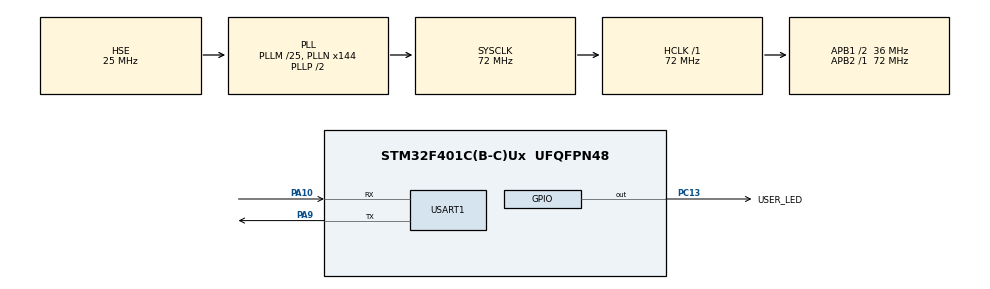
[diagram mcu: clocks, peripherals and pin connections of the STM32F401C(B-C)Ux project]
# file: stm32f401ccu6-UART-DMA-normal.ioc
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Dma.Request0=USART1_RX
Dma.USART1_RX.0.Direction=DMA_PERIPH_TO_MEMORY
Dma.USART1_RX.0.FIFOMode=DMA_FIFOMODE_DISABLE
Dma.USART1_RX.0.Instance=DMA2_Stream5
Dma.USART1_RX.0.MemDataAlignment=DMA_MDATAALIGN_BYTE
Dma.USART1_RX.0.MemInc=DMA_MINC_ENABLE
Dma.USART1_RX.0.Mode=DMA_NORMAL
Dma.USART1_RX.0.PeriphDataAlignment=DMA_PDATAALIGN_BYTE
Dma.USART1_RX.0.PeriphInc=DMA_PINC_DISABLE
Dma.USART1_RX.0.Priority=DMA_PRIORITY_LOW
Mcu.Family=STM32F4
Mcu.Name=STM32F401C(B-C)Ux
Mcu.Package=UFQFPN48
NVIC.DMA2_Stream5_IRQn=true\:0\:0\:false\:false\:true\:false\:true\:true
NVIC.PriorityGroup=NVIC_PRIORITYGROUP_4
PA10.Mode=Asynchronous
PA10.Signal=USART1_RX
PA13.Mode=Serial_Wire
PA13.Signal=SYS_JTMS-SWDIO
PA14.Mode=Serial_Wire
PA14.Signal=SYS_JTCK-SWCLK
PA9.Mode=Asynchronous
PA9.Signal=USART1_TX
PC13-ANTI_TAMP.GPIO_Label=USER_LED
PC13-ANTI_TAMP.Signal=GPIO_Output
PH0\ -\ OSC_IN.Mode=HSE-External-Oscillator
PH0\ -\ OSC_IN.Signal=RCC_OSC_IN
PH1\ -\ OSC_OUT.Mode=HSE-External-Oscillator
PH1\ -\ OSC_OUT.Signal=RCC_OSC_OUT
ProjectManager.HeapSize=0x200
ProjectManager.StackSize=0x400
ProjectManager.TargetToolchain=STM32CubeIDE
RCC.48MHZClocksFreq_Value=36000000
RCC.AHBFreq_Value=72000000
RCC.APB1CLKDivider=RCC_HCLK_DIV2
RCC.APB1Freq_Value=36000000
RCC.APB1TimFreq_Value=72000000
RCC.APB2Freq_Value=72000000
RCC.APB2TimFreq_Value=72000000
RCC.CortexFreq_Value=72000000
RCC.HCLKFreq_Value=72000000
RCC.HSE_VALUE=25000000
RCC.HSI_VALUE=16000000
RCC.LSE_VALUE=32768
RCC.PLLM=25
RCC.PLLN=144
RCC.PLLSourceVirtual=RCC_PLLSOURCE_HSE
RCC.SYSCLKFreq_VALUE=72000000
RCC.SYSCLKSource=RCC_SYSCLKSOURCE_PLLCLK
RCC.VCOOutputFreq_Value=144000000
USART1.VirtualMode=VM_ASYNC
board=custom

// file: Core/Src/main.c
/* USER CODE BEGIN Header */
/**
  ******************************************************************************
  * @file           : main.c
  * @brief          : Main program body
  ******************************************************************************
  * @attention
  *
  * Copyright (c) 2025 STMicroelectronics.
  * All rights reserved.
  *
  * This software is licensed under terms that can be found in the LICENSE file
  * in the root directory of this software component.
  * If no LICENSE file comes with this software, it is provided AS-IS.
  *
  ******************************************************************************
  */
/* USER CODE END Header */
#include "main.h"

/* USER CODE BEGIN Includes */
#include "string.h"
#include "stdio.h"
/* USER CODE END Includes */

UART_HandleTypeDef huart1;
DMA_HandleTypeDef hdma_usart1_rx;

void SystemClock_Config(void);
static void MX_GPIO_Init(void);
static void MX_DMA_Init(void);
static void MX_USART1_UART_Init(void);
/* USER CODE BEGIN PFP */

void DMA_buffer_parser();

/* USER CODE END PFP */

/* USER CODE BEGIN 0 */

uint8_t rx_data[12] = {0};
volatile uint8_t dma_recv_complete = 0;

/* USER CODE END 0 */

int main(void)
{

  /* MCU Configuration--------------------------------------------------------*/

  /* Reset of all peripherals, Initializes the Flash interface and the Systick. */
  HAL_Init();

  /* Configure the system clock */
  SystemClock_Config();

  /* Initialize all configured peripherals */
  MX_GPIO_Init();
  MX_DMA_Init();
  MX_USART1_UART_Init();
  /* USER CODE BEGIN 2 */

  HAL_UART_Receive_DMA(&huart1, rx_data, 12);

  /* USER CODE END 2 */

  /* Infinite loop */
  while (1)
  {

    /* USER CODE BEGIN 3 */

//	  HAL_GPIO_TogglePin(USER_LED_GPIO_Port, USER_LED_Pin);
//	  HAL_Delay(700);

	  DMA_buffer_parser();

  }
  /* USER CODE END 3 */
}

void SystemClock_Config(void)
{
  RCC_OscInitTypeDef RCC_OscInitStruct = {0};
  RCC_ClkInitTypeDef RCC_ClkInitStruct = {0};

  /** Configure the main internal regulator output voltage
  */
  __HAL_RCC_PWR_CLK_ENABLE();
  __HAL_PWR_VOLTAGESCALING_CONFIG(PWR_REGULATOR_VOLTAGE_SCALE2);

  /** Initializes the RCC Oscillators according to the specified parameters
  * in the RCC_OscInitTypeDef structure.
  */
  RCC_OscInitStruct.OscillatorType = RCC_OSCILLATORTYPE_HSE;
  RCC_OscInitStruct.HSEState = RCC_HSE_ON;
  RCC_OscInitStruct.PLL.PLLState = RCC_PLL_ON;
  RCC_OscInitStruct.PLL.PLLSource = RCC_PLLSOURCE_HSE;
  RCC_OscInitStruct.PLL.PLLM = 25;
  RCC_OscInitStruct.PLL.PLLN = 144;
  RCC_OscInitStruct.PLL.PLLP = RCC_PLLP_DIV2;
  RCC_OscInitStruct.PLL.PLLQ = 4;
  if (HAL_RCC_OscConfig(&RCC_OscInitStruct) != HAL_OK)
  {
    Error_Handler();
  }

  /** Initializes the CPU, AHB and APB buses clocks
  */
  RCC_ClkInitStruct.ClockType = RCC_CLOCKTYPE_HCLK|RCC_CLOCKTYPE_SYSCLK
                              |RCC_CLOCKTYPE_PCLK1|RCC_CLOCKTYPE_PCLK2;
  RCC_ClkInitStruct.SYSCLKSource = RCC_SYSCLKSOURCE_PLLCLK;
  RCC_ClkInitStruct.AHBCLKDivider = RCC_SYSCLK_DIV1;
  RCC_ClkInitStruct.APB1CLKDivider = RCC_HCLK_DIV2;
  RCC_ClkInitStruct.APB2CLKDivider = RCC_HCLK_DIV1;

  if (HAL_RCC_ClockConfig(&RCC_ClkInitStruct, FLASH_LATENCY_2) != HAL_OK)
  {
    Error_Handler();
  }
}

static void MX_USART1_UART_Init(void)
{

  huart1.Instance = USART1;
  huart1.Init.BaudRate = 115200;
  huart1.Init.WordLength = UART_WORDLENGTH_8B;
  huart1.Init.StopBits = UART_STOPBITS_1;
  huart1.Init.Parity = UART_PARITY_NONE;
  huart1.Init.Mode = UART_MODE_TX_RX;
  huart1.Init.HwFlowCtl = UART_HWCONTROL_NONE;
  huart1.Init.OverSampling = UART_OVERSAMPLING_16;
  if (HAL_UART_Init(&huart1) != HAL_OK)
  {
    Error_Handler();
  }

}

static void MX_DMA_Init(void)
{

  /* DMA controller clock enable */
  __HAL_RCC_DMA2_CLK_ENABLE();

  /* DMA interrupt init */
  /* DMA2_Stream5_IRQn interrupt configuration */
  HAL_NVIC_SetPriority(DMA2_Stream5_IRQn, 0, 0);
  HAL_NVIC_EnableIRQ(DMA2_Stream5_IRQn);

}

static void MX_GPIO_Init(void)
{
  GPIO_InitTypeDef GPIO_InitStruct = {0};

  /* GPIO Ports Clock Enable */
  __HAL_RCC_GPIOC_CLK_ENABLE();
  __HAL_RCC_GPIOH_CLK_ENABLE();
  __HAL_RCC_GPIOA_CLK_ENABLE();

  /*Configure GPIO pin Output Level */
  HAL_GPIO_WritePin(USER_LED_GPIO_Port, USER_LED_Pin, GPIO_PIN_RESET);

  /*Configure GPIO pin : USER_LED_Pin */
  GPIO_InitStruct.Pin = USER_LED_Pin;
  GPIO_InitStruct.Mode = GPIO_MODE_OUTPUT_PP;
  GPIO_InitStruct.Pull = GPIO_NOPULL;
  GPIO_InitStruct.Speed = GPIO_SPEED_FREQ_LOW;
  HAL_GPIO_Init(USER_LED_GPIO_Port, &GPIO_InitStruct);

}

/* USER CODE BEGIN 4 */

void HAL_UART_RxCpltCallback(UART_HandleTypeDef* huart) {
	dma_recv_complete = 1;
	// HAL_UART_Transmit(&huart1, (uint8_t*)"DMA_BUFF: ", strlen("DMA_BUFF: "), 10);
	// HAL_UART_Transmit(&huart1, rx_data, 12, 100);

}

// parser received message
void DMA_buffer_parser() {
	if(dma_recv_complete == 1) {
		dma_recv_complete = 0;

		 // parse by delimiter
		 // make length a fixed variable
		 char s = '$';
		 char st = '\r';
		 uint8_t s_index = 0;
		 uint8_t stp_index = 0;

		 char b[25];

		 // look for start character
		 for(int i =0; i < 12; i++) {
			 if(rx_data[i]  != s) {
				 continue;
			 } else {
				 s_index = i;
			 }
		 }

		 // look for stop character
		 for(int i =0; i < 12; i++) {
			 if(rx_data[i]  != st) {
				 continue;
			 } else {
				 stp_index = i;
			 }
		 }

		 // extract type of message e.g GPGGA
		 char sen_type[6]; // the first 5 characters represne the sentence type
		 char val[5];
		 for(int i = s_index + 1; i < 6; i++) {
			 sen_type[i] = rx_data[i];
		 }
		 sen_type[6] = '\0'; // nul terminate

		 sprintf(b, "sentype: %s \r\n", sen_type);
		 //HAL_UART_Transmit(&huart1, (uint8_t*) b, strlen(b), 100);

		 HAL_UART_Transmit(&huart1, (uint8_t*) sen_type, strlen(b), 100);

		 // restart DMA to continuously receive DMA data
		 HAL_UART_Receive_DMA(&huart1, rx_data, 12);

	}
}

/* USER CODE END 4 */

void Error_Handler(void)
{
  __disable_irq();
  while (1)
  {
  }
}
